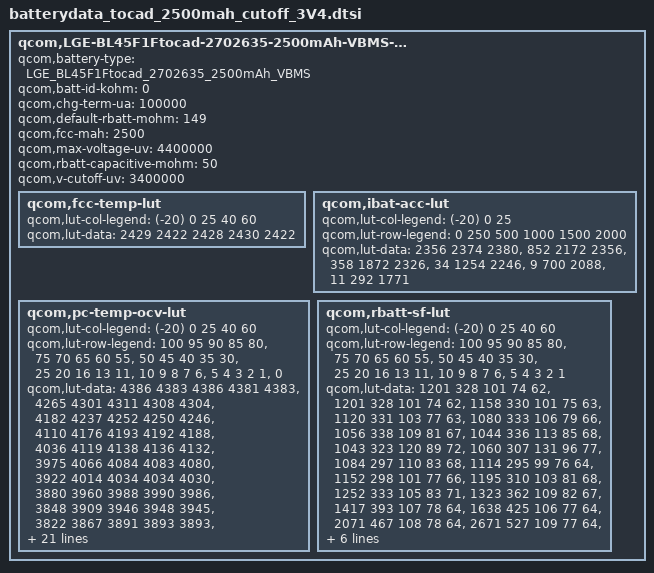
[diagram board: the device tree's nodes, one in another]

qcom,LGE-BL45F1Ftocad-2702635-2500mAh-VBMS-batterydata {
	qcom,battery-type = "LGE_BL45F1Ftocad_2702635_2500mAh_VBMS";
	qcom,batt-id-kohm = <0>;
	qcom,chg-term-ua = <100000>;
	qcom,default-rbatt-mohm = <149>;
	qcom,fcc-mah = <2500>;
	qcom,max-voltage-uv = <4400000>;
	qcom,rbatt-capacitive-mohm = <50>;
	qcom,v-cutoff-uv = <3400000>;

	qcom,fcc-temp-lut {
		qcom,lut-col-legend = <(-20) 0 25 40 60>;
		qcom,lut-data = <2429 2422 2428 2430 2422>;
	};

	qcom,ibat-acc-lut {
		qcom,lut-col-legend = <(-20) 0 25>;
		qcom,lut-row-legend = <0 250 500 1000 1500 2000>;
		qcom,lut-data = <2356 2374 2380>,
				<852 2172 2356>,
				<358 1872 2326>,
				<34 1254 2246>,
				<9 700 2088>,
				<11 292 1771>;
	};

	qcom,pc-temp-ocv-lut {
		qcom,lut-col-legend = <(-20) 0 25 40 60>;
		qcom,lut-row-legend = <100 95 90 85 80>,
					<75 70 65 60 55>,
					<50 45 40 35 30>,
					<25 20 16 13 11>,
					<10 9 8 7 6>,
					<5 4 3 2 1>,
					<0>;
		qcom,lut-data = <4386 4383 4386 4381 4383>,
				<4265 4301 4311 4308 4304>,
				<4182 4237 4252 4250 4246>,
				<4110 4176 4193 4192 4188>,
				<4036 4119 4138 4136 4132>,
				<3975 4066 4084 4083 4080>,
				<3922 4014 4034 4034 4030>,
				<3880 3960 3988 3990 3986>,
				<3848 3909 3946 3948 3945>,
				<3822 3867 3891 3893 3893>,
				<3798 3834 3852 3854 3854>,
				<3776 3808 3826 3828 3828>,
				<3753 3790 3805 3808 3808>,
				<3732 3778 3788 3790 3790>,
				<3712 3764 3774 3773 3766>,
				<3694 3746 3758 3754 3741>,
				<3674 3720 3738 3732 3718>,
				<3654 3696 3711 3706 3692>,
				<3634 3683 3688 3683 3670>,
				<3616 3675 3682 3678 3667>,
				<3605 3670 3680 3676 3666>,
				<3591 3666 3678 3675 3664>,
				<3576 3660 3676 3674 3662>,
				<3556 3652 3672 3670 3658>,
				<3531 3638 3666 3664 3644>,
				<3496 3614 3643 3636 3608>,
				<3454 3575 3600 3587 3556>,
				<3397 3520 3536 3520 3486>,
				<3321 3442 3450 3432 3388>,
				<3207 3312 3315 3288 3234>,
				<3000 3000 3000 3000 3000>;
	};

	qcom,rbatt-sf-lut {
		qcom,lut-col-legend = <(-20) 0 25 40 60>;
		qcom,lut-row-legend = <100 95 90 85 80>,
					<75 70 65 60 55>,
					<50 45 40 35 30>,
					<25 20 16 13 11>,
					<10 9 8 7 6>,
					<5 4 3 2 1>;
		qcom,lut-data = <1201 328 101 74 62>,
				<1201 328 101 74 62>,
				<1158 330 101 75 63>,
				<1120 331 103 77 63>,
				<1080 333 106 79 66>,
				<1056 338 109 81 67>,
				<1044 336 113 85 68>,
				<1043 323 120 89 72>,
				<1060 307 131 96 77>,
				<1084 297 110 83 68>,
				<1114 295 99 76 64>,
				<1152 298 101 77 66>,
				<1195 310 103 81 68>,
				<1252 333 105 83 71>,
				<1323 362 109 82 67>,
				<1417 393 107 78 64>,
				<1638 425 106 77 64>,
				<2071 467 108 78 64>,
				<2671 527 109 77 64>,
				<3328 597 111 79 65>,
				<3745 634 114 81 66>,
				<4277 682 120 82 68>,
				<4705 718 123 84 68>,
				<5372 739 126 85 70>,
				<6866 809 132 86 68>,
				<9367 908 134 83 67>,
				<13732 1051 138 84 68>,
				<22103 1366 148 89 72>,
				<40881 2321 171 97 81>,
				<81762 4642 223 123 162>;
	};
};
